# ESP32S31_RADIO register map
Vendor: Espressif; Series: ESP32-S31; File version: 3.52
Registers are 32-bit, read-write, no defined reset value unless marked. A register's access mark holds for its fields unless they carry their own. Offsets are from the block's base; [hi:lo] are bit positions; {n}, {i} and the like mark numbered series.

## BLE_CONTROLLER_ADDRESS_SLOTS — Three positional six-byte controller address slots. A complete ESP32-S31 ble_phy.c leaf proves the selector range, pair stride, byte packing and write order. Named callers identify public-address use of slot zero and random-address use of slot one; slot two remains intentionally unnamed.
Base 0x2010180C
{0x0+8i} SLOT{i}_LOW (i=0..2) wo — Project-assigned name. Bytes zero through three of the selected six-byte value, packed in little-endian order and written before the paired high word.
  [31:0] OCTETS_0_TO_3 — Project-assigned name. The complete low word assembled from input bytes zero through three.
{0x4+8i} SLOT{i}_HIGH (i=0..2) wo — Project-assigned name. Bytes four and five of the selected six-byte value in bits 0..15; the complete write clears bits 16..31.
  [15:0] OCTETS_4_TO_5 — Project-assigned name. Input bytes four and five packed in little-endian order.

## BLE_SYNC_PUBLICATION — Two positional write-only words used by one ble_lll_sync.c path. The source identity records software context only; the register names deliberately do not turn that context into an undocumented hardware meaning.
Base 0x20101878
0x00 VALUE_0 wo — Project-assigned name. One runtime-derived complete 32-bit image.
  [31:0] VALUE — Project-assigned name.
0x04 VALUE_1 wo — Project-assigned name. One runtime-derived low-24-bit image; the complete publication writes bits 24..31 as zero.
  [23:0] IMAGE_LOW_24 — Project-assigned name.

## BLE_SCAN_BACKOFF — Scan-backoff state of the Link Layer scanner (Core Specification Vol 6, Part B, 4.4.3.2). Scanner start publishes the maximum upper limit and initializes the two hardware-maintained backoff words to one; a vendor test command reads those two words back as nine-bit values. Which word is the backoff count and which the upper limit is not established.
Base 0x20101970
0x00 UPPER_LIMIT_MAX wo — Project-assigned name. Maximum scan-backoff upper limit. Scanner start writes the Controller configuration's nine-bit upper limit, 32 in the S31 build, or 1 when backoff is disabled.
  [8:0] VALUE — Project-assigned name.
0x04 BACKOFF_STATE_0 — Project-assigned name. One of the two hardware-maintained backoff words (upper limit or backoff count); scanner start writes one.
  [8:0] VALUE — Project-assigned name.
0x08 BACKOFF_STATE_1 — Project-assigned name. The other hardware-maintained backoff word; scanner start writes one.
  [8:0] VALUE — Project-assigned name.

## BLE_HW_RESOLVING_LIST — Narrow owner for the standalone BLE resolving-list base publication. The complete ESP32-S31 ble_hw.c leaf proves one compressed SRAM pointer word but does not prove that adjacent BTMAC addresses belong to the same logical block.
Base 0x20101880
0x00 BASE_POINTER wo — Project-assigned name. Complete image equal to the caller-provided SRAM address shifted right by two and truncated to twenty bits.
  [19:0] COMPRESSED_SRAM_POINTER — Project-assigned name. Bits 0..19 contain address >> 2; bits 20..31 are written as zero.

## BLE_HW_RUNTIME_CONTROL — Sparse BLE hardware status/clear and runtime-configuration view. Complete ESP32-S31 functions prove the array geometry, access directions and exact configuration images. Positional names retain unknown source and field semantics instead of promoting diagnostic strings to hardware truth.
Base 0x20101B00
{0x30+4i} STATUS{i} (i=0..7) ro — Project-assigned name. Complete status word read once for each of eight sources before optional diagnostic reporting.
  [31:0] PENDING_BITS — Project-assigned name.
{0x50+4i} CLEAR{i} (i=0..7) wo — Project-assigned name. Paired clear word receiving the complete image 0xFFFFFFFF for each of eight sources.
  [31:0] PENDING_BITS — Project-assigned name.
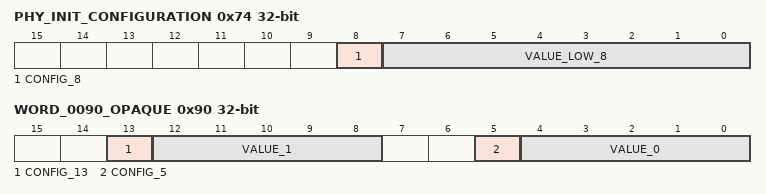
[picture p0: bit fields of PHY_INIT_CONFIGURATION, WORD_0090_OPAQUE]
0x74 PHY_INIT_CONFIGURATION wo — Project-assigned name. Complete BLE PHY initialization publishes one runtime-derived low byte together with finite bit 8 as a whole-word image. The byte encoding remains unknown.
  [8] CONFIG_8 — Project-assigned name.
  [7:0] VALUE_LOW_8 — Project-assigned name.
0x78 PHY_INIT_CONFIGURATION_FOLLOWUP wo — Project-assigned name. Complete BLE PHY initialization writes the finite complete image one immediately after PHY_INIT_CONFIGURATION. The hardware meaning of this ordered follow-up write remains unknown.
  [31:0] VALUE — Project-assigned name.
0x88 WORD_0088_OPAQUE wo — Opaque: meaning not established. Complete image formed from the low five bits of one controller configuration byte.
  [4:0] VALUE_LOW_5 — Project-assigned name.
0x90 WORD_0090_OPAQUE wo — Opaque: meaning not established. Complete image formed from two low-five-bit controller values in bits 0..4 and 8..12 plus finite one bits at positions 5 and 13.
  [13] CONFIG_13 — Project-assigned name.
  [12:8] VALUE_1 — Project-assigned name.
  [5] CONFIG_5 — Project-assigned name.
  [4:0] VALUE_0 — Project-assigned name.
0x94 WORD_0094_OPAQUE wo — Opaque: meaning not established. Complete image formed from one controller configuration byte.
  [7:0] VALUE_LOW_8 — Project-assigned name.
